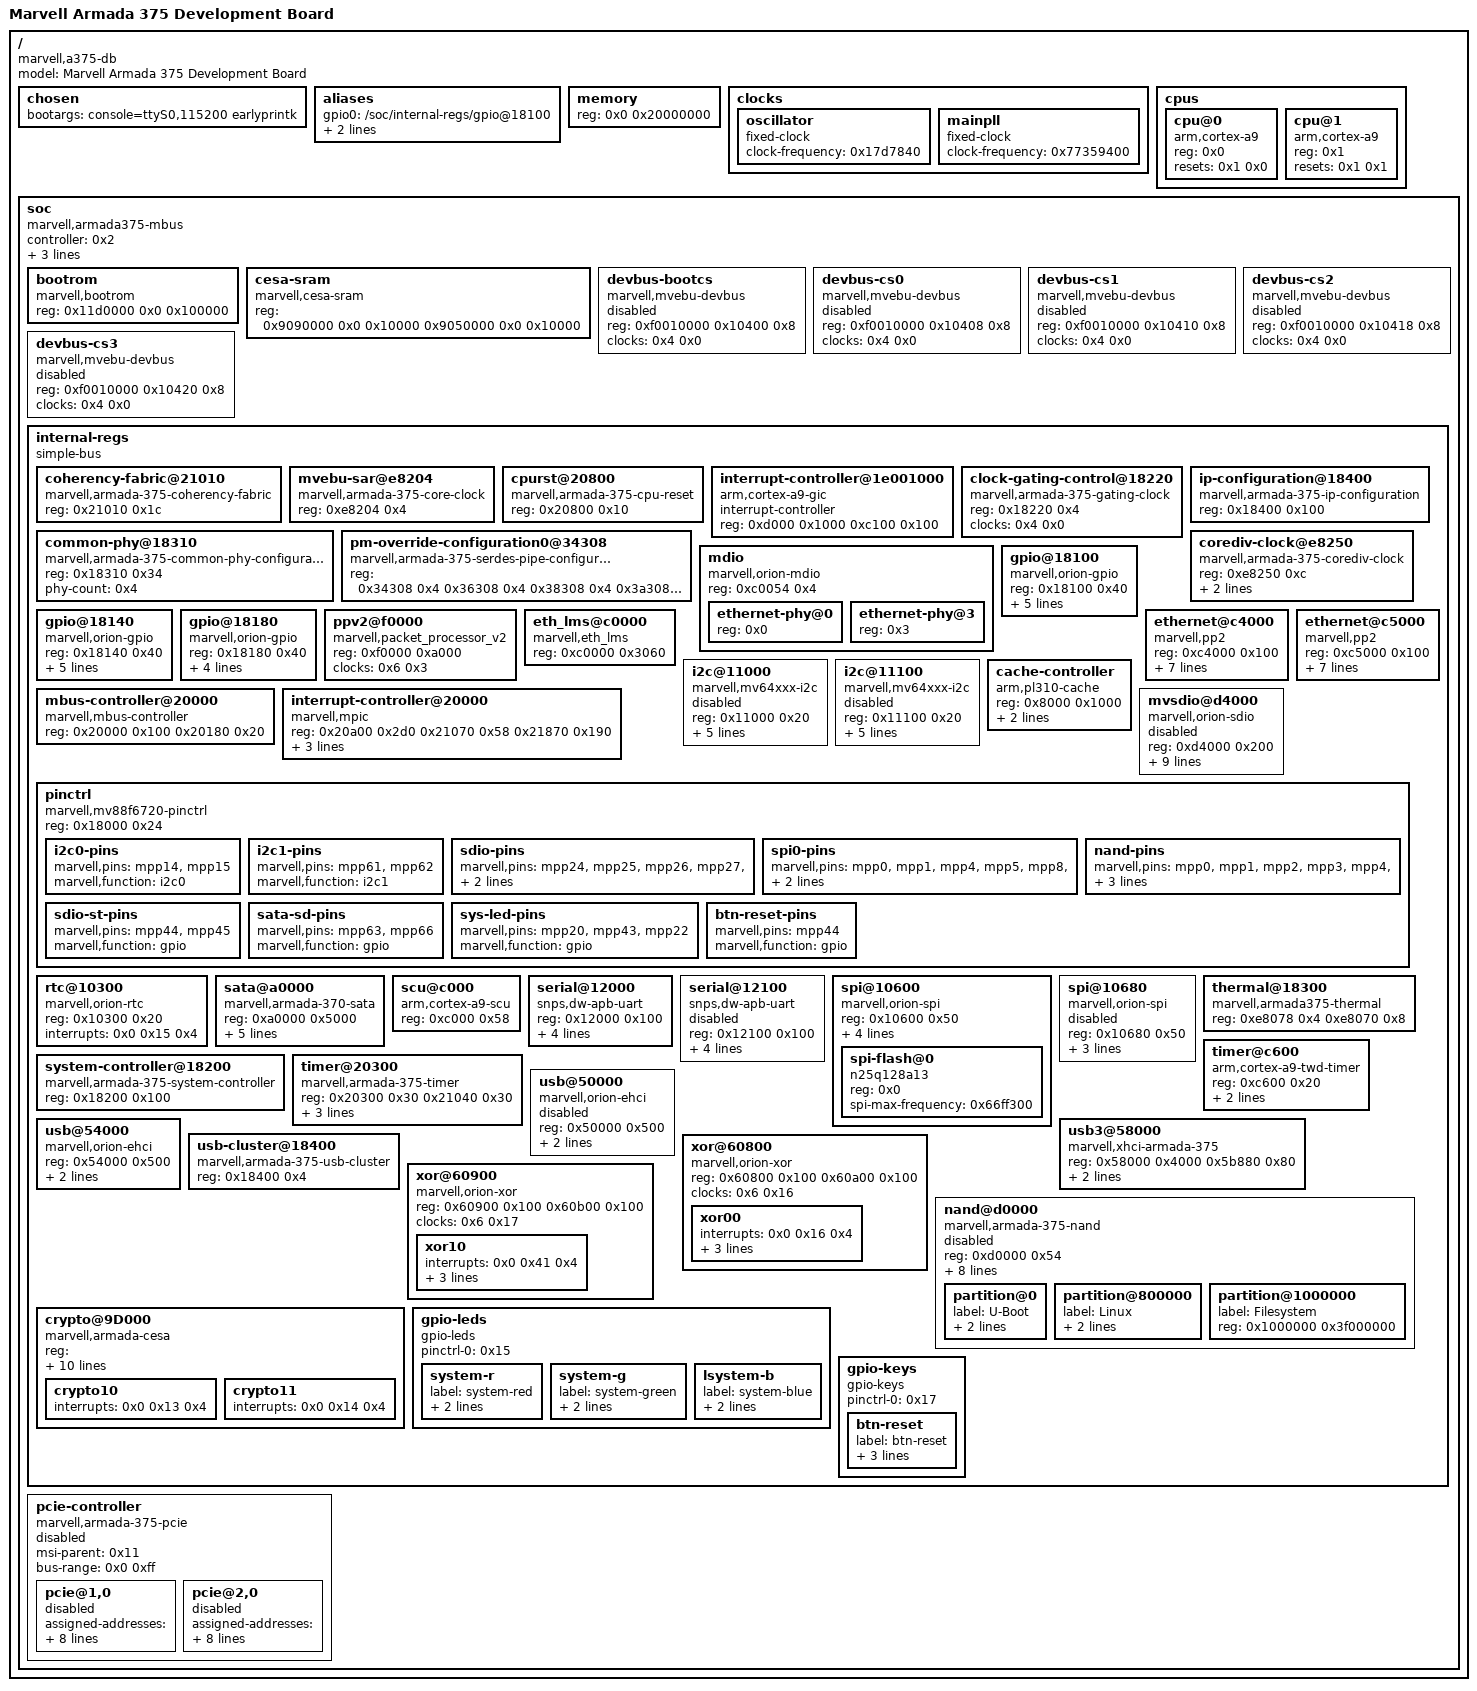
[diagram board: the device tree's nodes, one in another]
/dts-v1/;

/ {
	#address-cells = <0x1>;
	#size-cells = <0x1>;
	model = "Marvell Armada 375 Development Board";
	compatible = "marvell,a375-db", "marvell,armada375";

	chosen {
		bootargs = "console=ttyS0,115200 earlyprintk";
	};

	aliases {
		gpio0 = "/soc/internal-regs/gpio@18100";
		gpio1 = "/soc/internal-regs/gpio@18140";
		gpio2 = "/soc/internal-regs/gpio@18180";
	};

	memory {
		device_type = "memory";
		reg = <0x0 0x20000000>;
	};

	clocks {

		oscillator {
			compatible = "fixed-clock";
			#clock-cells = <0x0>;
			clock-frequency = <0x17d7840>;
			linux,phandle = <0x12>;
			phandle = <0x12>;
		};

		mainpll {
			compatible = "fixed-clock";
			#clock-cells = <0x0>;
			clock-frequency = <0x77359400>;
			linux,phandle = <0x5>;
			phandle = <0x5>;
		};
	};

	cpus {
		#address-cells = <0x1>;
		#size-cells = <0x0>;

		cpu@0 {
			device_type = "cpu";
			compatible = "arm,cortex-a9";
			reg = <0x0>;
			resets = <0x1 0x0>;
		};

		cpu@1 {
			device_type = "cpu";
			compatible = "arm,cortex-a9";
			reg = <0x1>;
			resets = <0x1 0x1>;
		};
	};

	soc {
		compatible = "marvell,armada375-mbus", "simple-bus";
		#address-cells = <0x2>;
		#size-cells = <0x1>;
		controller = <0x2>;
		interrupt-parent = <0x3>;
		pcie-mem-aperture = <0xe0000000 0x8000000>;
		pcie-io-aperture = <0xe8000000 0x100000>;
		ranges = <0xf0010000 0x0 0xf1000000 0x100000 0x11d0000 0x0 0xfff00000 0x100000 0x9090000 0x0 0xf1100000 0x10000 0x9050000 0x0 0xf1110000 0x10000>;

		bootrom {
			compatible = "marvell,bootrom";
			reg = <0x11d0000 0x0 0x100000>;
		};

		cesa-sram {
			compatible = "marvell,cesa-sram";
			reg = <0x9090000 0x0 0x10000 0x9050000 0x0 0x10000>;
		};

		devbus-bootcs {
			compatible = "marvell,mvebu-devbus";
			reg = <0xf0010000 0x10400 0x8>;
			ranges = <0x0 0x12f0000 0x0 0xffffffff>;
			#address-cells = <0x1>;
			#size-cells = <0x1>;
			clocks = <0x4 0x0>;
			status = "disabled";
		};

		devbus-cs0 {
			compatible = "marvell,mvebu-devbus";
			reg = <0xf0010000 0x10408 0x8>;
			ranges = <0x0 0x13e0000 0x0 0xffffffff>;
			#address-cells = <0x1>;
			#size-cells = <0x1>;
			clocks = <0x4 0x0>;
			status = "disabled";
		};

		devbus-cs1 {
			compatible = "marvell,mvebu-devbus";
			reg = <0xf0010000 0x10410 0x8>;
			ranges = <0x0 0x13d0000 0x0 0xffffffff>;
			#address-cells = <0x1>;
			#size-cells = <0x1>;
			clocks = <0x4 0x0>;
			status = "disabled";
		};

		devbus-cs2 {
			compatible = "marvell,mvebu-devbus";
			reg = <0xf0010000 0x10418 0x8>;
			ranges = <0x0 0x13b0000 0x0 0xffffffff>;
			#address-cells = <0x1>;
			#size-cells = <0x1>;
			clocks = <0x4 0x0>;
			status = "disabled";
		};

		devbus-cs3 {
			compatible = "marvell,mvebu-devbus";
			reg = <0xf0010000 0x10420 0x8>;
			ranges = <0x0 0x1370000 0x0 0xffffffff>;
			#address-cells = <0x1>;
			#size-cells = <0x1>;
			clocks = <0x4 0x0>;
			status = "disabled";
		};

		internal-regs {
			compatible = "simple-bus";
			#address-cells = <0x1>;
			#size-cells = <0x1>;
			ranges = <0x0 0xf0010000 0x0 0x100000>;

			coherency-fabric@21010 {
				compatible = "marvell,armada-375-coherency-fabric";
				reg = <0x21010 0x1c>;
			};

			mvebu-sar@e8204 {
				compatible = "marvell,armada-375-core-clock";
				reg = <0xe8204 0x4>;
				#clock-cells = <0x1>;
				linux,phandle = <0x4>;
				phandle = <0x4>;
			};

			cpurst@20800 {
				compatible = "marvell,armada-375-cpu-reset";
				reg = <0x20800 0x10>;
				#reset-cells = <0x1>;
				linux,phandle = <0x1>;
				phandle = <0x1>;
			};

			interrupt-controller@1e001000 {
				compatible = "arm,cortex-a9-gic";
				#interrupt-cells = <0x3>;
				#size-cells = <0x0>;
				interrupt-controller;
				reg = <0xd000 0x1000 0xc100 0x100>;
				linux,phandle = <0x3>;
				phandle = <0x3>;
			};

			clock-gating-control@18220 {
				compatible = "marvell,armada-375-gating-clock";
				reg = <0x18220 0x4>;
				clocks = <0x4 0x0>;
				#clock-cells = <0x1>;
				linux,phandle = <0x6>;
				phandle = <0x6>;
			};

			common-phy@18310 {
				compatible = "marvell,armada-375-common-phy-configuration";
				reg = <0x18310 0x34>;
				status = "okay";
				phy-count = <0x4>;
			};

			ip-configuration@18400 {
				compatible = "marvell,armada-375-ip-configuration";
				reg = <0x18400 0x100>;
			};

			pm-override-configuration0@34308 {
				compatible = "marvell,armada-375-serdes-pipe-configuration";
				reg = <0x34308 0x4 0x36308 0x4 0x38308 0x4 0x3a308 0x4>;
			};

			corediv-clock@e8250 {
				compatible = "marvell,armada-375-corediv-clock";
				reg = <0xe8250 0xc>;
				#clock-cells = <0x1>;
				clocks = <0x5>;
				clock-output-names = "nand";
				linux,phandle = <0x13>;
				phandle = <0x13>;
			};

			mdio {
				#address-cells = <0x1>;
				#size-cells = <0x0>;
				compatible = "marvell,orion-mdio";
				reg = <0xc0054 0x4>;

				ethernet-phy@0 {
					reg = <0x0>;
					linux,phandle = <0x7>;
					phandle = <0x7>;
				};

				ethernet-phy@3 {
					reg = <0x3>;
					linux,phandle = <0x8>;
					phandle = <0x8>;
				};
			};

			gpio@18100 {
				compatible = "marvell,orion-gpio";
				reg = <0x18100 0x40>;
				ngpios = <0x20>;
				gpio-controller;
				#gpio-cells = <0x2>;
				interrupt-controller;
				#interrupt-cells = <0x2>;
				interrupts = <0x0 0x35 0x4 0x0 0x36 0x4 0x0 0x37 0x4 0x0 0x38 0x4>;
				linux,phandle = <0x16>;
				phandle = <0x16>;
			};

			gpio@18140 {
				compatible = "marvell,orion-gpio";
				reg = <0x18140 0x40>;
				ngpios = <0x20>;
				gpio-controller;
				#gpio-cells = <0x2>;
				interrupt-controller;
				#interrupt-cells = <0x2>;
				interrupts = <0x0 0x3a 0x4 0x0 0x3b 0x4 0x0 0x3c 0x4 0x0 0x3d 0x4>;
				linux,phandle = <0xd>;
				phandle = <0xd>;
			};

			gpio@18180 {
				compatible = "marvell,orion-gpio";
				reg = <0x18180 0x40>;
				ngpios = <0x3>;
				gpio-controller;
				#gpio-cells = <0x2>;
				interrupt-controller;
				#interrupt-cells = <0x2>;
				interrupts = <0x0 0x3e 0x4>;
				linux,phandle = <0xf>;
				phandle = <0xf>;
			};

			ppv2@f0000 {
				compatible = "marvell,packet_processor_v2";
				reg = <0xf0000 0xa000>;
				clocks = <0x6 0x3>;
			};

			eth_lms@c0000 {
				compatible = "marvell,eth_lms";
				reg = <0xc0000 0x3060>;
			};

			ethernet@c4000 {
				compatible = "marvell,pp2";
				reg = <0xc4000 0x100>;
				interrupts = <0x0 0x25 0x1>;
				clocks = <0x6 0x13>;
				mac-address = [00 50 43 02 02 00];
				eth,port-num = <0x0>;
				eth,port-mtu = <0x5dc>;
				status = "okay";
				phy = <0x7>;
				phy-mode = "mii";
			};

			ethernet@c5000 {
				compatible = "marvell,pp2";
				reg = <0xc5000 0x100>;
				interrupts = <0x0 0x29 0x1>;
				clocks = <0x6 0x13>;
				mac-address = [00 50 43 02 02 01];
				eth,port-num = <0x1>;
				eth,port-mtu = <0x5dc>;
				status = "okay";
				phy = <0x8>;
				phy-mode = "mii";
			};

			i2c@11000 {
				compatible = "marvell,mv64xxx-i2c";
				reg = <0x11000 0x20>;
				#address-cells = <0x1>;
				#size-cells = <0x0>;
				interrupts = <0x0 0x2 0x4>;
				timeout-ms = <0x3e8>;
				clocks = <0x4 0x0>;
				status = "disabled";
				clock-frequency = <0x186a0>;
				pinctrl-0 = <0x9>;
				pinctrl-names = "default";
			};

			i2c@11100 {
				compatible = "marvell,mv64xxx-i2c";
				reg = <0x11100 0x20>;
				#address-cells = <0x1>;
				#size-cells = <0x0>;
				interrupts = <0x0 0x3 0x4>;
				timeout-ms = <0x3e8>;
				clocks = <0x4 0x0>;
				status = "disabled";
				clock-frequency = <0x186a0>;
				pinctrl-0 = <0xa>;
				pinctrl-names = "default";
			};

			cache-controller {
				compatible = "arm,pl310-cache";
				reg = <0x8000 0x1000>;
				cache-unified;
				cache-level = <0x2>;
			};

			mbus-controller@20000 {
				compatible = "marvell,mbus-controller";
				reg = <0x20000 0x100 0x20180 0x20>;
				linux,phandle = <0x2>;
				phandle = <0x2>;
			};

			interrupt-controller@20000 {
				compatible = "marvell,mpic";
				reg = <0x20a00 0x2d0 0x21070 0x58 0x21870 0x190>;
				#interrupt-cells = <0x1>;
				#size-cells = <0x1>;
				interrupt-controller;
				msi-controller;
				interrupts = <0x1 0xf 0x4>;
				linux,phandle = <0x11>;
				phandle = <0x11>;
			};

			mvsdio@d4000 {
				compatible = "marvell,orion-sdio";
				reg = <0xd4000 0x200>;
				interrupts = <0x0 0x19 0x4>;
				clocks = <0x6 0x11>;
				bus-width = <0x4>;
				cap-sdio-irq;
				cap-sd-highspeed;
				cap-mmc-highspeed;
				status = "disabled";
				pinctrl-0 = <0xb 0xc>;
				pinctrl-names = "default";
				cd-gpios = <0xd 0xc 0x0>;
				wp-gpios = <0xd 0xd 0x0>;
			};

			pinctrl {
				compatible = "marvell,mv88f6720-pinctrl";
				reg = <0x18000 0x24>;

				i2c0-pins {
					marvell,pins = "mpp14", "mpp15";
					marvell,function = "i2c0";
					linux,phandle = <0x9>;
					phandle = <0x9>;
				};

				i2c1-pins {
					marvell,pins = "mpp61", "mpp62";
					marvell,function = "i2c1";
					linux,phandle = <0xa>;
					phandle = <0xa>;
				};

				sdio-pins {
					marvell,pins = "mpp24", "mpp25", "mpp26", "mpp27", "mpp28", "mpp29";
					marvell,function = "sd";
					linux,phandle = <0xb>;
					phandle = <0xb>;
				};

				spi0-pins {
					marvell,pins = "mpp0", "mpp1", "mpp4", "mpp5", "mpp8", "mpp9";
					marvell,function = "spi0";
					linux,phandle = <0x10>;
					phandle = <0x10>;
				};

				nand-pins {
					marvell,pins = "mpp0", "mpp1", "mpp2", "mpp3", "mpp4", "mpp5", "mpp6", "mpp7", "mpp8", "mpp9", "mpp10", "mpp11", "mpp12", "mpp13";
					marvell,function = "nand";
					linux,phandle = <0x14>;
					phandle = <0x14>;
				};

				sdio-st-pins {
					marvell,pins = "mpp44", "mpp45";
					marvell,function = "gpio";
					linux,phandle = <0xc>;
					phandle = <0xc>;
				};

				sata-sd-pins {
					marvell,pins = "mpp63", "mpp66";
					marvell,function = "gpio";
					linux,phandle = <0xe>;
					phandle = <0xe>;
				};

				sys-led-pins {
					marvell,pins = "mpp20", "mpp43", "mpp22";
					marvell,function = "gpio";
					linux,phandle = <0x15>;
					phandle = <0x15>;
				};

				btn-reset-pins {
					marvell,pins = "mpp44";
					marvell,function = "gpio";
					linux,phandle = <0x17>;
					phandle = <0x17>;
				};
			};

			rtc@10300 {
				compatible = "marvell,orion-rtc";
				reg = <0x10300 0x20>;
				interrupts = <0x0 0x15 0x4>;
			};

			sata@a0000 {
				compatible = "marvell,armada-370-sata";
				reg = <0xa0000 0x5000>;
				interrupts = <0x0 0x1a 0x4>;
				clocks = <0x6 0xe 0x6 0x14>;
				clock-names = <0x30003100>;
				status = "okay";
				nr-ports = <0x2>;
				pinctrl-0 = <0xe>;
				pinctrl-names = "default";
				sd-gpios = <0xd 0x1f 0x0 0xf 0x2 0x0>;
			};

			scu@c000 {
				compatible = "arm,cortex-a9-scu";
				reg = <0xc000 0x58>;
			};

			serial@12000 {
				compatible = "snps,dw-apb-uart";
				reg = <0x12000 0x100>;
				reg-shift = <0x2>;
				interrupts = <0x0 0xc 0x4>;
				reg-io-width = <0x1>;
				clocks = <0x4 0x0>;
				status = "okay";
			};

			serial@12100 {
				compatible = "snps,dw-apb-uart";
				reg = <0x12100 0x100>;
				reg-shift = <0x2>;
				interrupts = <0x0 0xd 0x4>;
				reg-io-width = <0x1>;
				clocks = <0x4 0x0>;
				status = "disabled";
			};

			spi@10600 {
				compatible = "marvell,orion-spi";
				reg = <0x10600 0x50>;
				#address-cells = <0x1>;
				#size-cells = <0x0>;
				cell-index = <0x0>;
				interrupts = <0x0 0x1 0x4>;
				clocks = <0x4 0x0>;
				status = "okay";
				pinctrl-0 = <0x10>;
				pinctrl-names = "default";

				spi-flash@0 {
					#address-cells = <0x1>;
					#size-cells = <0x1>;
					compatible = "n25q128a13";
					reg = <0x0>;
					spi-max-frequency = <0x66ff300>;
				};
			};

			spi@10680 {
				compatible = "marvell,orion-spi";
				reg = <0x10680 0x50>;
				#address-cells = <0x1>;
				#size-cells = <0x0>;
				cell-index = <0x1>;
				interrupts = <0x0 0x3f 0x4>;
				clocks = <0x4 0x0>;
				status = "disabled";
			};

			system-controller@18200 {
				compatible = "marvell,armada-375-system-controller";
				reg = <0x18200 0x100>;
			};

			thermal@18300 {
				compatible = "marvell,armada375-thermal";
				reg = <0xe8078 0x4 0xe8070 0x8>;
				status = "okay";
			};

			timer@c600 {
				compatible = "arm,cortex-a9-twd-timer";
				reg = <0xc600 0x20>;
				interrupts = <0x1 0xd 0x301>;
				clocks = <0x4 0x2>;
			};

			timer@20300 {
				compatible = "marvell,armada-375-timer";
				reg = <0x20300 0x30 0x21040 0x30>;
				interrupts-extended = <0x3 0x0 0x8 0x4 0x3 0x0 0x9 0x4 0x3 0x0 0xa 0x4 0x3 0x0 0xb 0x4 0x11 0x5 0x11 0x6>;
				clocks = <0x4 0x2 0x12>;
				clock-names = "nbclk", "fixed";
			};

			usb@50000 {
				compatible = "marvell,orion-ehci";
				reg = <0x50000 0x500>;
				interrupts = <0x0 0x11 0x4>;
				clocks = <0x6 0x12>;
				status = "disabled";
			};

			usb@54000 {
				compatible = "marvell,orion-ehci";
				reg = <0x54000 0x500>;
				interrupts = <0x0 0x12 0x4>;
				clocks = <0x6 0x1a>;
				status = "okay";
			};

			usb3@58000 {
				compatible = "marvell,xhci-armada-375";
				reg = <0x58000 0x4000 0x5b880 0x80>;
				interrupts = <0x0 0x10 0x4>;
				clocks = <0x6 0x10>;
				status = "okay";
			};

			usb-cluster@18400 {
				compatible = "marvell,armada-375-usb-cluster";
				reg = <0x18400 0x4>;
			};

			xor@60800 {
				compatible = "marvell,orion-xor";
				reg = <0x60800 0x100 0x60a00 0x100>;
				clocks = <0x6 0x16>;
				status = "okay";

				xor00 {
					interrupts = <0x0 0x16 0x4>;
					dmacap,memcpy;
					dmacap,xor;
					dmacap,interrupt;
				};
			};

			xor@60900 {
				compatible = "marvell,orion-xor";
				reg = <0x60900 0x100 0x60b00 0x100>;
				clocks = <0x6 0x17>;
				status = "okay";

				xor10 {
					interrupts = <0x0 0x41 0x4>;
					dmacap,memcpy;
					dmacap,xor;
					dmacap,interrupt;
				};
			};

			nand@d0000 {
				compatible = "marvell,armada-375-nand";
				reg = <0xd0000 0x54>;
				#address-cells = <0x1>;
				#size-cells = <0x1>;
				interrupts = <0x0 0x54 0x4>;
				clocks = <0x13 0x0 0x6 0xb>;
				clock-names = "ecc_clk", "gateclk";
				status = "disabled";
				pinctrl-0 = <0x14>;
				pinctrl-names = "default";
				nfc,nfc-mode = "normal";
				nfc,nfc-dma = <0x0>;
				nfc,nfc-width = <0x8>;
				nfc,ecc-type = <0x1>;
				nfc,num-cs = <0x1>;

				partition@0 {
					label = "U-Boot";
					reg = <0x0 0x800000>;
					read-only;
				};

				partition@800000 {
					label = "Linux";
					reg = <0x800000 0x800000>;
					read-only;
				};

				partition@1000000 {
					label = "Filesystem";
					reg = <0x1000000 0x3f000000>;
				};
			};

			crypto@9D000 {
				compatible = "marvell,armada-cesa";
				reg = <0x9d000 0x1000 0x90000 0x1000 0x9f000 0x1000 0x92000 0x1000>;
				clocks = <0x6 0x1e 0x6 0x1c 0x6 0x1f 0x6 0x1d>;
				clock-names = "crypto0", "crypto0z", "crypto1", "crypto1z";
				cesa,channels = <0x2>;
				cesa,mode = "ocf";
				cesa,feature = "int_coalescing";
				cesa,threshold = <0x2>;
				cesa,time_threshold = <0xff>;
				cesa,ctrlModel = [67 20];
				cesa,ctrlRev = [02];
				cesa,sramOffset = [00 00];
				status = "okay";

				crypto10 {
					interrupts = <0x0 0x13 0x4>;
				};

				crypto11 {
					interrupts = <0x0 0x14 0x4>;
				};
			};

			gpio-leds {
				compatible = "gpio-leds";
				pinctrl-names = "default";
				pinctrl-0 = <0x15>;

				system-r {
					label = "system-red";
					gpios = <0x16 0x14 0x0>;
					linux,default-trigger = "default-on";
				};

				system-g {
					label = "system-green";
					gpios = <0xd 0xb 0x0>;
					linux,default-trigger = "default-on";
				};

				lsystem-b {
					label = "system-blue";
					gpios = <0x16 0x16 0x0>;
					linux,default-trigger = "default-on";
				};
			};

			gpio-keys {
				compatible = "gpio-keys";
				pinctrl-names = "default";
				pinctrl-0 = <0x17>;
				#address-cells = <0x1>;
				#size-cells = <0x0>;

				btn-reset {
					label = "btn-reset";
					gpios = <0xd 0xc 0x0>;
					linux,code = <0xc6>;
					gpio-key,wakeup;
				};
			};
		};

		pcie-controller {
			compatible = "marvell,armada-375-pcie";
			status = "disabled";
			device_type = "pci";
			#address-cells = <0x3>;
			#size-cells = <0x2>;
			msi-parent = <0x11>;
			bus-range = <0x0 0xff>;
			ranges = <0x82000000 0x0 0x40000 0xf0010000 0x40000 0x0 0x2000 0x82000000 0x0 0x44000 0xf0010000 0x44000 0x0 0x2000 0x82000000 0x1 0x0 0x4e80000 0x0 0x1 0x0 0x81000000 0x1 0x0 0x4e00000 0x0 0x1 0x0 0x82000000 0x2 0x0 0x4d80000 0x0 0x1 0x0 0x81000000 0x2 0x0 0x4d00000 0x0 0x1 0x0>;

			pcie@1,0 {
				device_type = "pci";
				assigned-addresses = <0x82000800 0x0 0x40000 0x0 0x2000>;
				reg = <0x800 0x0 0x0 0x0 0x0>;
				#address-cells = <0x3>;
				#size-cells = <0x2>;
				#interrupt-cells = <0x1>;
				ranges = <0x82000000 0x0 0x0 0x82000000 0x1 0x0 0x1 0x0 0x81000000 0x0 0x0 0x81000000 0x1 0x0 0x1 0x0>;
				interrupt-map-mask = <0x0 0x0 0x0 0x0>;
				interrupt-map = <0x0 0x0 0x0 0x0 0x3 0x0 0x1d 0x4>;
				marvell,pcie-port = <0x0>;
				marvell,pcie-lane = <0x0>;
				clocks = <0x6 0x5>;
				status = "disabled";
			};

			pcie@2,0 {
				device_type = "pci";
				assigned-addresses = <0x82000800 0x0 0x44000 0x0 0x2000>;
				reg = <0x1000 0x0 0x0 0x0 0x0>;
				#address-cells = <0x3>;
				#size-cells = <0x2>;
				#interrupt-cells = <0x1>;
				ranges = <0x82000000 0x0 0x0 0x82000000 0x2 0x0 0x1 0x0 0x81000000 0x0 0x0 0x81000000 0x2 0x0 0x1 0x0>;
				interrupt-map-mask = <0x0 0x0 0x0 0x0>;
				interrupt-map = <0x0 0x0 0x0 0x0 0x3 0x0 0x21 0x4>;
				marvell,pcie-port = <0x0>;
				marvell,pcie-lane = <0x1>;
				clocks = <0x6 0x6>;
				status = "disabled";
			};
		};
	};
};
